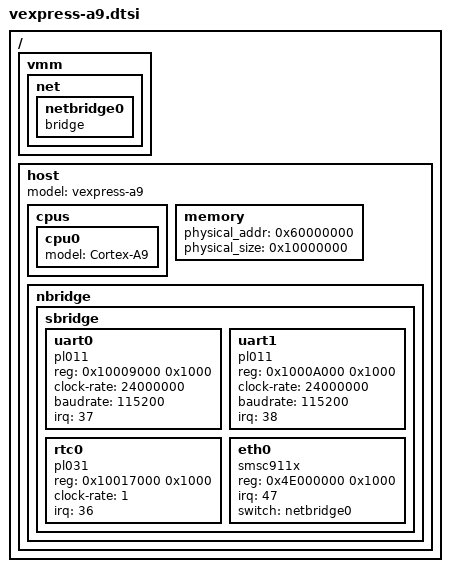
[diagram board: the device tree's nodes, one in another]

/ {
	vmm {
		net {
			netbridge0 {
				device_type = "netswitch";
				compatible = "bridge";
			};
		};
	};

	host {
		model = "vexpress-a9";
		device_type = "host";
		
		cpus {
			cpu0 {
				device_type = "cpu";
				model = "Cortex-A9";
			};
		};

		memory {
			/* NOTE: By default QEMU will only proivde 128 MB 
			 * unless specified by "-m" option. If you have
			 * X MB then we will be able to access only first
			 * X MB starting at physical_addr.
			 */
			physical_addr = <0x60000000>;
			physical_size = <0x10000000>; /* 256 MB */
		};

		nbridge {
			sbridge {
				#address-cells = <1>;
				#size-cells = <1>;

				uart0 {
			      		device_type = "serial";
			      		compatible = "pl011";
			      		reg = <0x10009000 0x1000>;
					clock-rate = <24000000>;
			      		baudrate = <115200>;
					irq = <37>;
				};

				uart1 {
			      		device_type = "serial";
			      		compatible = "pl011";
			      		reg = <0x1000A000 0x1000>;
					clock-rate = <24000000>;
			      		baudrate = <115200>;
					irq = <38>;
				};

				rtc0 {
			      		device_type = "rtc";
			      		compatible = "pl031";
			      		reg = <0x10017000 0x1000>;
					clock-rate = <1>;
					irq = <36>;
				};

				eth0 {
					device_type = "nic";
					compatible = "smsc911x";
					reg = <0x4E000000 0x1000>;
					irq = <47>;
					switch = "netbridge0";
				};
			};
		};
	};
};
